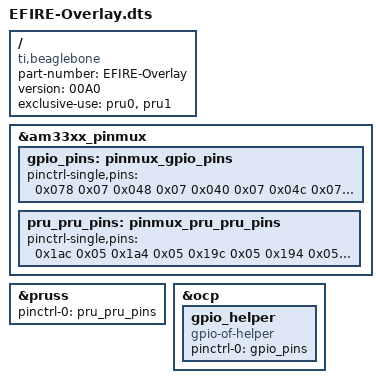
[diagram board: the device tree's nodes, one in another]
/* 
   E-FIRE Senior Design Project, Boston University
   John Marcao
   Overlay file for enabling the pins necessary for interaction with the MIROC2
   This file has been adapted from Derek Molloy's book "Exploring BeagleBone Black"
   
   Version 0.4
     - After some testing and getting familiar with the BBB PRU-ICSS restrictions, We reformated some pins
         - Triggers have been split into two groups, default (DE) and test (TE) pins
               - Default pins are mapped to PRU1_R31 for parallel capture
               - Test pins are mapped to GPIO_2 pins. This will slow down data capture, but will not be used unless testing the channels
         - ADDR has been moved to GPIO_0 pins due to its low priority (no need for high speed)
         - Data-In has been moved to accomadate other pins
         - P&H Reset and Mux Enabled have been moved to GPIO_1 pins for simplicity
     - SPI/UART will be added once finalized
*/

/dts-v1/;
/plugin/;

/ {
   compatible = "ti,beaglebone", "ti,beaglebone-black";

   part-number = "EFIRE-Overlay";
   version = "00A0";

   /* This overlay uses the following resources */
   exclusive-use =
         "pru0", "pru1";

   fragment@0 {
      target = <&am33xx_pinmux>;
      __overlay__ {

         // Typical GPIO Pins available to the Linux OS.
         gpio_pins: pinmux_gpio_pins {
            pinctrl-single,pins = <

            //Output GPIO Pins
               // MUX Enable + P&H Reset
               0x078 0x07  // P9_12, GPIO_1_28, LSB 0001 - MUX_0 Enable
               0x048 0x07  // P9_14, GPIO_1_18      0010 - MUX_1 Enable
               0x040 0x07  // P9_15, GPIO_1_16      0100 - MUX_2 Enable
               0x04c 0x07  // P9_16, GPIO_1_19, MSB 1000 - P&H Reset

               // Address Pins
               0x020 0x07  // P8_19, GPIO_0_22
               0x0d8 0x07  // P8_31, GPIO_0_10
               0x0dc 0x07  // P8_32, GPIO_0_11
               0x0d4 0x07  // P8_33, GPIO_0_9
               0x0d0 0x07  // P8_35, GPIO_0_8

            //Input GPIO Pins
               //Trigger Inputs (Test, Slow)
               0x090 0x27  // P8_07, GPIO_2_2
               0x094 0x27  // P8_08, GPIO_2_3
               0x09c 0x27  // P8_09, GPIO_2_5
               0x098 0x27  // P8_10, GPIO_2_4
               0x08C 0x27  // P8_18, GPIO_2_1
               0x0c8 0x27  // P8_36, GPIO_2_16
               0x0c0 0x27  // P8_37, GPIO_2_14

            >;
         };

         // Enhanced GPIO Pins with direct PRU memory access
         pru_pru_pins: pinmux_pru_pru_pins {   // The PRU pin modes
            pinctrl-single,pins = <

            //Output PRU Pins
               // ADC Start
               0x1ac 0x05  // P9_25 pr1_pru0_pru_r30_7, ADC0 Start Output
               0x1a4 0x05  // P9_27 pr1_pru0_pru_r30_5, ADC1 Start Output
               0x19c 0x05  // P9_28 pr1_pru0_pru_r31_3, ADC2 Start Output

               // ADC Clock
               0x194 0x05  // P9_29 pr1_pru0_pru_r30_1, ADC0 Clock Output
               0x198 0x05  // P9_30 pr1_pru0_pru_r30_2, ADC1 Clock Output
               0x190 0x05  // P9_31 pr1_pru0_pru_r30_3, ADC2 Clock Output

            //Input PRU Pins
               //Trigger Inputs (Default, Fast)
               0x0e0 0x06  // P8_27 pr1_pru1_pru_r31_8
               0x0e8 0x06  // P8_28 pr1_pru1_pru_r31_10
               0x0e4 0x06  // P8_29 pr1_pru1_pru_r31_9
               0x0ec 0x06  // P8_30 pr1_pru1_pru_r31_11
               0x0b8 0x06  // P8_39 pr1_pru1_pru_r31_6
               0x0bc 0x06  // P8_40 pr1_pru1_pru_r31_7
               0x0b0 0x06  // P8_41 pr1_pru1_pru_r31_4
               0x0b4 0x06  // P8_42 pr1_pru1_pru_r31_5
               0x0a8 0x06  // P8_43 pr1_pru1_pru_r31_2
               0x0ac 0x06  // P8_44 pr1_pru1_pru_r31_3
               0x0a0 0x06  // P8_45 pr1_pru1_pru_r31_0
               0x0a4 0x06  // P8_46 pr1_pru1_pru_r31_1

               // Data Input
               0x03c 0x06  //P8_15 pr1_pru0_pru_r31_15, ADC0
               0x038 0x06  //P8_16 pr1_pru0_pru_r31_14, ADC1
               0x184 0x06  //P9_24 pr1_pru0_pru_r31_16, ADC2
            >;
         };
      };
   };

   fragment@1 {         // Enable the PRUSS
      target = <&pruss>;
      __overlay__ {
         status = "okay";
         pinctrl-names = "default";
         pinctrl-0 = <&pru_pru_pins>;
      };
   };

   fragment@2 {         // Enable the GPIOs
      target = <&ocp>;
      __overlay__ {
         gpio_helper {
            compatible = "gpio-of-helper";
            status = "okay";
            pinctrl-names = "default";
            pinctrl-0 = <&gpio_pins>;
         };
      };
   };
};
